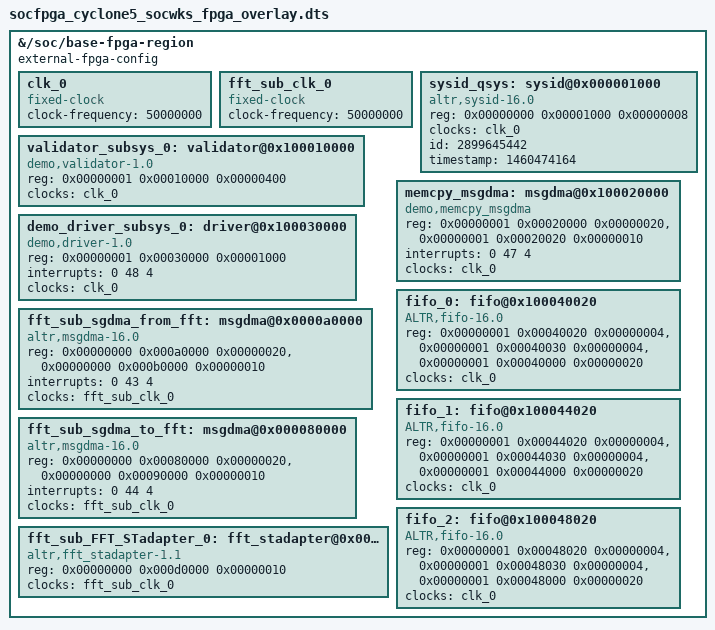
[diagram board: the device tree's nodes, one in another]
/*
 * Copyright Altera Corporation (C) 2015. All rights reserved.
 *
 * This program is free software; you can redistribute it and/or modify
 * it under the terms and conditions of the GNU General Public License,
 * version 2, as published by the Free Software Foundation.
 *
 * This program is distributed in the hope it will be useful, but WITHOUT
 * ANY WARRANTY; without even the implied warranty of MERCHANTABILITY or
 * FITNESS FOR A PARTICULAR PURPOSE.  See the GNU General Public License for
 * more details.
 *
 * You should have received a copy of the GNU General Public License along with
 * this program.  If not, see <http://www.gnu.org/licenses/>.
 */

 /dts-v1/ /plugin/;
/ {
	
	fragment@0 {
		target-path = "/soc/base-fpga-region";
		
		#address-cells = <2>;
		#size-cells = <1>;
		__overlay__ {
			#address-cells = <2>;
			#size-cells = <1>;
			
			external-fpga-config;
					
			clk_0: clk_0 {
				compatible = "fixed-clock";	
				clock-frequency = <50000000>;
			};
			
			fft_sub_clk_0: fft_sub_clk_0 {
				compatible = "fixed-clock";
				clock-frequency = <50000000>;
			}; 			
			
			sysid_qsys: sysid@0x000001000 {
				compatible = "altr,sysid-16.0", "altr,sysid-1.0";
				reg = <0x00000000 0x00001000 0x00000008>;
				clocks = <&clk_0>;
				id = <2899645442>;	/* embeddedsw.dts.params.id type NUMBER */
				timestamp = <1460474164>;	/* embeddedsw.dts.params.timestamp type NUMBER */
			};
			
			validator_subsys_0: validator@0x100010000 {
				compatible = "demo,validator-1.0", "demo,validator-1.0";
				reg = <0x00000001 0x00010000 0x00000400>;
				clocks = <&clk_0>;
			};
			
			demo_driver_subsys_0: driver@0x100030000 {
				compatible = "demo,driver-1.0", "demo,driver-1.0";
				reg = <0x00000001 0x00030000 0x00001000>;
				interrupts = <0 48 4>;
				clocks = <&clk_0>;
			}; 
			
			fft_sub_sgdma_from_fft: msgdma@0x0000a0000 {
				compatible = "altr,msgdma-16.0", "altr,msgdma-1.0";
				reg = <0x00000000 0x000a0000 0x00000020>,
					<0x00000000 0x000b0000 0x00000010>;
				reg-names = "csr", "descriptor_slave";
				interrupts = <0 43 4>;
				clocks = <&fft_sub_clk_0>;
			};

			fft_sub_sgdma_to_fft: msgdma@0x000080000 {
				compatible = "altr,msgdma-16.0", "altr,msgdma-1.0";
				reg = <0x00000000 0x00080000 0x00000020>,
					<0x00000000 0x00090000 0x00000010>;
				reg-names = "csr", "descriptor_slave";
				interrupts = <0 44 4>;
				clocks = <&fft_sub_clk_0>;
			}; 

			fft_sub_FFT_STadapter_0: fft_stadapter@0x0000d0000 {
				compatible = "altr,fft_stadapter-1.1", "altr,fft_stadapter";
				reg = <0x00000000 0x000d0000 0x00000010>;
				clocks = <&fft_sub_clk_0>;
			}; 			
			
			memcpy_msgdma: msgdma@0x100020000 {
				compatible = "demo,memcpy_msgdma";	/* appended from boardinfo */
				reg = <0x00000001 0x00020000 0x00000020>,
					<0x00000001 0x00020020 0x00000010>;
				reg-names = "csr", "descriptor_slave";
				interrupts = <0 47 4>;
				clocks = <&clk_0>;
			}; 	
			
			fifo_0: fifo@0x100040020 {
				compatible = "ALTR,fifo-16.0", "ALTR,fifo-1.0";
				reg = <0x00000001 0x00040020 0x00000004>,
					<0x00000001 0x00040030 0x00000004>,
					<0x00000001 0x00040000 0x00000020>;
				reg-names = "in", "out", "in_csr";
				clocks = <&clk_0>;
			}; 

			fifo_1: fifo@0x100044020 {
				compatible = "ALTR,fifo-16.0", "ALTR,fifo-1.0";
				reg = <0x00000001 0x00044020 0x00000004>,
					<0x00000001 0x00044030 0x00000004>,
					<0x00000001 0x00044000 0x00000020>;
				reg-names = "in", "out", "in_csr";
				clocks = <&clk_0>;
			}; 

			fifo_2: fifo@0x100048020 {
				compatible = "ALTR,fifo-16.0", "ALTR,fifo-1.0";
				reg = <0x00000001 0x00048020 0x00000004>,
					<0x00000001 0x00048030 0x00000004>,
					<0x00000001 0x00048000 0x00000020>;
				reg-names = "in", "out", "in_csr";
				clocks = <&clk_0>;
			}; 			
				 
		};
		

	};
};
